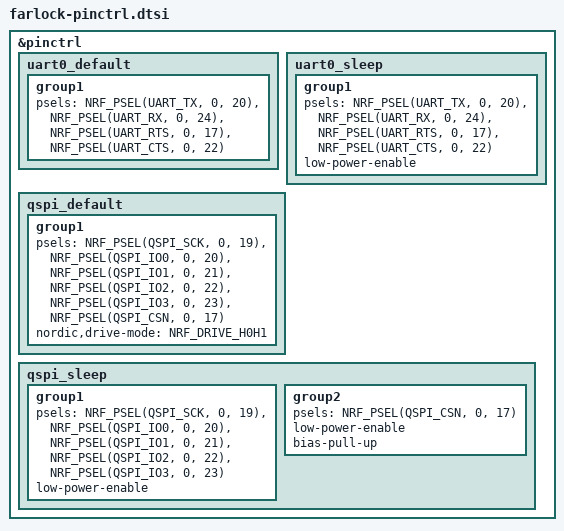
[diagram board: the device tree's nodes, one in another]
&pinctrl {
	uart0_default: uart0_default {
		group1 {
			psels = <NRF_PSEL(UART_TX, 0, 20)>,
					<NRF_PSEL(UART_RX, 0, 24)>,
					<NRF_PSEL(UART_RTS, 0, 17)>,
					<NRF_PSEL(UART_CTS, 0, 22)>;
		};
	};

	uart0_sleep: uart0_sleep {
		group1 {
			psels = <NRF_PSEL(UART_TX, 0, 20)>,
					<NRF_PSEL(UART_RX, 0, 24)>,
					<NRF_PSEL(UART_RTS, 0, 17)>,
					<NRF_PSEL(UART_CTS, 0, 22)>;
			low-power-enable;
		};
	};

	qspi_default: qspi_default {
		group1 {
			psels = <NRF_PSEL(QSPI_SCK, 0, 19)>,
					<NRF_PSEL(QSPI_IO0, 0, 20)>,
					<NRF_PSEL(QSPI_IO1, 0, 21)>,
					<NRF_PSEL(QSPI_IO2, 0, 22)>,
					<NRF_PSEL(QSPI_IO3, 0, 23)>,
					<NRF_PSEL(QSPI_CSN, 0, 17)>;
			nordic,drive-mode = <NRF_DRIVE_H0H1>;
		};
	};

	qspi_sleep: qspi_sleep {
		group1 {
			psels = <NRF_PSEL(QSPI_SCK, 0, 19)>,
					<NRF_PSEL(QSPI_IO0, 0, 20)>,
					<NRF_PSEL(QSPI_IO1, 0, 21)>,
					<NRF_PSEL(QSPI_IO2, 0, 22)>,
					<NRF_PSEL(QSPI_IO3, 0, 23)>;
			low-power-enable;
		};
		group2 {
			psels = <NRF_PSEL(QSPI_CSN, 0, 17)>;
			low-power-enable;
			bias-pull-up;
		};
	};

};
